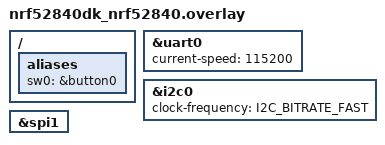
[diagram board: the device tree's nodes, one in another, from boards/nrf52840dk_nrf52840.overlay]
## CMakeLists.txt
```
cmake_minimum_required(VERSION 3.20.0)
find_package(Zephyr REQUIRED HINTS $ENV{ZEPHYR_BASE})
project(zephyr_edge_telemetry_nrf52840)

target_sources(app PRIVATE
  src/main.c
  src/app/app_config.c
  src/drivers/sensor_bus.c
  src/drivers/irq_button.c
  src/pipeline/sampler.c
  src/pipeline/pipeline_math.c
  src/pipeline/processor.c
  src/connectivity/net_client.c
  src/connectivity/ws_client.c
  src/connectivity/rest_gateway.c
  src/control/control_plane.c
)

target_include_directories(app PRIVATE include)
```

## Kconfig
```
menu "Edge Telemetry Node"

config EDGE_NODE_ID
	string "Node identifier"
	default "nrf52840-node-01"

config EDGE_SAMPLE_PERIOD_MS
	int "Sensor sampling period (ms)"
	range 10 60000
	default 100

config EDGE_REST_POLL_MS
	int "REST command poll period (ms)"
	range 1000 120000
	default 5000

config EDGE_PIPELINE_QUEUE_DEPTH
	int "Pipeline queue depth"
	range 4 128
	default 32

config EDGE_TELEMETRY_HOST
	string "Telemetry gateway host"
	default "192.168.1.10"

config EDGE_TELEMETRY_PORT
	int "Telemetry TCP/WebSocket port"
	range 1 65535
	default 9000

config EDGE_REST_PORT
	int "REST gateway port"
	range 1 65535
	default 8080

config EDGE_WS_URL
	string "WebSocket URL"
	default "/ws/telemetry"

config EDGE_REST_URL
	string "REST command URL"
	default "/api/v1/command"

endmenu
```

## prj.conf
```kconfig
CONFIG_MAIN_STACK_SIZE=4096
CONFIG_HEAP_MEM_POOL_SIZE=16384

# Logging/UART
CONFIG_SERIAL=y
CONFIG_CONSOLE=y
CONFIG_UART_CONSOLE=y
CONFIG_LOG=y
CONFIG_LOG_MODE_DEFERRED=y
CONFIG_LOG_DEFAULT_LEVEL=3
CONFIG_LOG_BUFFER_SIZE=8192

# Kernel primitives and diagnostics
CONFIG_THREAD_NAME=y
CONFIG_THREAD_MONITOR=y
CONFIG_ASSERT=y
CONFIG_INIT_STACKS=y
CONFIG_STACK_SENTINEL=y

# Watchdog strategy
CONFIG_TASK_WDT=y
CONFIG_TASK_WDT_CHANNELS=8

# Workqueue and timing
CONFIG_SYSTEM_WORKQUEUE_STACK_SIZE=3072

# Drivers/protocol buses
CONFIG_GPIO=y
CONFIG_I2C=y
CONFIG_SPI=y

# Networking and sockets
CONFIG_NETWORKING=y
CONFIG_NET_NATIVE=y
CONFIG_NET_IPV4=y
CONFIG_NET_IPV6=n
CONFIG_NET_TCP=y
CONFIG_NET_UDP=n
CONFIG_NET_SOCKETS=y
CONFIG_NET_SOCKETS_POSIX_NAMES=y
CONFIG_NET_DHCPV4=y
CONFIG_DNS_RESOLVER=y
CONFIG_NET_CONFIG_SETTINGS=y
CONFIG_NET_CONFIG_NEED_IPV4=y
CONFIG_NET_CONFIG_AUTO_INIT=y

# HTTP + WebSocket client
CONFIG_HTTP_CLIENT=y
CONFIG_WEBSOCKET_CLIENT=y
CONFIG_NET_BUF_RX_COUNT=64
CONFIG_NET_BUF_TX_COUNT=64
CONFIG_NET_PKT_RX_COUNT=16
CONFIG_NET_PKT_TX_COUNT=16

# libc helpers
CONFIG_NEWLIB_LIBC=y
CONFIG_NEWLIB_LIBC_FLOAT_PRINTF=y

# C++ support (for optional extensions)
CONFIG_CPP=y
CONFIG_STD_CPP17=y

# App defaults from Kconfig
CONFIG_EDGE_NODE_ID="nrf52840-node-01"
CONFIG_EDGE_SAMPLE_PERIOD_MS=100
CONFIG_EDGE_REST_POLL_MS=5000
CONFIG_EDGE_PIPELINE_QUEUE_DEPTH=32
CONFIG_EDGE_TELEMETRY_HOST="192.168.1.10"
CONFIG_EDGE_TELEMETRY_PORT=9000
CONFIG_EDGE_REST_PORT=8080
CONFIG_EDGE_WS_URL="/ws/telemetry"
CONFIG_EDGE_REST_URL="/api/v1/command"
```

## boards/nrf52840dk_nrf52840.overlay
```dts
/ {
	aliases {
		sw0 = &button0;
	};
};

&uart0 {
	status = "okay";
	current-speed = <115200>;
};

&i2c0 {
	status = "okay";
	clock-frequency = <I2C_BITRATE_FAST>;
};

&spi1 {
	status = "okay";
};
```

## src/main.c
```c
#include <zephyr/kernel.h>
#include <zephyr/logging/log.h>

#include <limits.h>

#include "app_config.h"
#include "control_plane.h"
#include "irq_button.h"
#include "processor.h"
#include "rest_gateway.h"
#include "rtos_channels.h"
#include "sampler.h"
#include "sensor_bus.h"
#include "ws_client.h"

LOG_MODULE_REGISTER(edge_main, LOG_LEVEL_INF);

K_MSGQ_DEFINE(edge_raw_sample_msgq,
              sizeof(struct edge_raw_sample),
              CONFIG_EDGE_PIPELINE_QUEUE_DEPTH,
              4);

K_MSGQ_DEFINE(edge_processed_sample_msgq,
              sizeof(struct edge_processed_sample),
              CONFIG_EDGE_PIPELINE_QUEUE_DEPTH,
              4);

K_MSGQ_DEFINE(edge_control_cmd_msgq,
              sizeof(struct edge_control_cmd),
              16,
              4);

K_MSGQ_DEFINE(edge_irq_event_msgq,
              sizeof(struct edge_irq_event),
              16,
              4);

K_SEM_DEFINE(edge_sample_trigger_sem, 0, UINT_MAX);
K_SEM_DEFINE(edge_work_done_sem, 0, UINT_MAX);
K_MUTEX_DEFINE(edge_network_mutex);

int main(void)
{
    int rc;

    LOG_INF("Zephyr Real-Time Edge Telemetry Node booting");

    app_config_init();

    rc = sensor_bus_init();
    if (rc < 0) {
        LOG_ERR("sensor_bus_init failed (%d)", rc);
    }

    rc = irq_button_init();
    if (rc < 0) {
        LOG_WRN("irq_button_init failed (%d), continuing", rc);
    }

    rc = control_plane_start();
    if (rc < 0) {
        LOG_ERR("control_plane_start failed (%d)", rc);
        return rc;
    }

    rc = processor_start();
    if (rc < 0) {
        LOG_ERR("processor_start failed (%d)", rc);
        return rc;
    }

    rc = sampler_start();
    if (rc < 0) {
        LOG_ERR("sampler_start failed (%d)", rc);
        return rc;
    }

    rc = ws_telemetry_start();
    if (rc < 0) {
        LOG_ERR("ws_telemetry_start failed (%d)", rc);
        return rc;
    }

    rc = rest_gateway_start();
    if (rc < 0) {
        LOG_ERR("rest_gateway_start failed (%d)", rc);
        return rc;
    }

    while (true) {
        struct edge_runtime_config cfg;
        app_config_get(&cfg);

        LOG_INF("alive: sample_period=%ums rest_poll=%ums ws=%s host=%s:%u rest_port=%u",
                cfg.sample_period_ms,
                cfg.rest_poll_ms,
                cfg.websocket_enabled ? "on" : "off",
                cfg.telemetry_host,
                cfg.telemetry_port,
                cfg.rest_port);

        k_sleep(K_SECONDS(10));
    }

    return 0;
}
```

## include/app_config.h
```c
#ifndef EDGE_APP_CONFIG_H_
#define EDGE_APP_CONFIG_H_

#include <stdbool.h>
#include <stdint.h>

struct edge_runtime_config {
    char node_id[48];
    char telemetry_host[64];
    uint16_t telemetry_port;
    uint16_t rest_port;
    char ws_url[96];
    char rest_url[96];
    uint32_t sample_period_ms;
    uint32_t rest_poll_ms;
    bool websocket_enabled;
};

void app_config_init(void);
void app_config_get(struct edge_runtime_config *out);
uint32_t app_config_get_sample_period_ms(void);
void app_config_set_sample_period_ms(uint32_t period_ms);
void app_config_set_websocket_enabled(bool enabled);

#endif
```

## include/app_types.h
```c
#ifndef EDGE_APP_TYPES_H_
#define EDGE_APP_TYPES_H_

#include <stdint.h>
#include <zephyr/sys/util.h>

#define EDGE_FLAGS_ISR_EVENT BIT(0)
#define EDGE_FLAGS_I2C_OK    BIT(1)
#define EDGE_FLAGS_SPI_OK    BIT(2)

enum edge_control_cmd_type {
    EDGE_CMD_SET_SAMPLE_PERIOD_MS = 1,
    EDGE_CMD_FORCE_FLUSH = 2,
    EDGE_CMD_FORCE_RECONNECT = 3,
};

enum edge_irq_event_type {
    EDGE_IRQ_BUTTON_PRESS = 1,
};

struct edge_raw_sample {
    uint32_t sequence;
    int64_t ts_ms;
    int16_t i2c_raw;
    int16_t spi_raw;
    uint8_t flags;
};

struct edge_processed_sample {
    uint32_t sequence;
    int64_t ts_ms;
    int16_t i2c_raw;
    int16_t spi_raw;
    int32_t fused_value;
    uint8_t quality;
    uint8_t flags;
};

struct edge_control_cmd {
    enum edge_control_cmd_type type;
    uint32_t value_u32;
};

struct edge_irq_event {
    enum edge_irq_event_type type;
    uint32_t count;
    int64_t ts_ms;
};

#endif
```

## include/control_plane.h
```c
#ifndef EDGE_CONTROL_PLANE_H_
#define EDGE_CONTROL_PLANE_H_

#include <stdbool.h>
#include <stdint.h>

int control_plane_start(void);
bool control_plane_consume_irq_latch(void);
int control_plane_watchdog_register(const char *owner, uint32_t reload_ms);
void control_plane_watchdog_feed(int channel_id);

#endif
```

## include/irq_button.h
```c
#ifndef EDGE_IRQ_BUTTON_H_
#define EDGE_IRQ_BUTTON_H_

int irq_button_init(void);

#endif
```

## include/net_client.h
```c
#ifndef EDGE_NET_CLIENT_H_
#define EDGE_NET_CLIENT_H_

#include <stdint.h>

int net_client_tcp_connect(const char *host, uint16_t port, int *sock_out);
int net_client_send_all(int sock, const uint8_t *buf, int len);
int net_client_recv_once(int sock, uint8_t *buf, int len, int timeout_ms);
void net_client_close(int *sock);

#endif
```

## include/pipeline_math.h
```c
#ifndef EDGE_PIPELINE_MATH_H_
#define EDGE_PIPELINE_MATH_H_

#include <stdint.h>

int32_t pipeline_compute_fused(int32_t previous, int16_t i2c_raw, int16_t spi_raw);

#endif
```

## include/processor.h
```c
#ifndef EDGE_PROCESSOR_H_
#define EDGE_PROCESSOR_H_

int processor_start(void);

#endif
```

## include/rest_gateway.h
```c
#ifndef EDGE_REST_GATEWAY_H_
#define EDGE_REST_GATEWAY_H_

#include "app_types.h"

int rest_gateway_start(void);
int rest_gateway_poll_command(struct edge_control_cmd *cmd_out);

#endif
```

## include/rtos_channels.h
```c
#ifndef EDGE_RTOS_CHANNELS_H_
#define EDGE_RTOS_CHANNELS_H_

#include <zephyr/kernel.h>

#include "app_types.h"

extern struct k_msgq edge_raw_sample_msgq;
extern struct k_msgq edge_processed_sample_msgq;
extern struct k_msgq edge_control_cmd_msgq;
extern struct k_msgq edge_irq_event_msgq;

extern struct k_sem edge_sample_trigger_sem;
extern struct k_sem edge_work_done_sem;

extern struct k_mutex edge_network_mutex;

#endif
```

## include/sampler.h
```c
#ifndef EDGE_SAMPLER_H_
#define EDGE_SAMPLER_H_

#include <stdint.h>

int sampler_start(void);
void sampler_update_period_ms(uint32_t period_ms);

#endif
```

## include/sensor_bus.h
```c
#ifndef EDGE_SENSOR_BUS_H_
#define EDGE_SENSOR_BUS_H_

#include "app_types.h"

int sensor_bus_init(void);
int sensor_bus_read(struct edge_raw_sample *sample);

#endif
```

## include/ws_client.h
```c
#ifndef EDGE_WS_CLIENT_H_
#define EDGE_WS_CLIENT_H_

#include <stdbool.h>
#include <stdint.h>

struct edge_ws_handle {
    int tcp_sock;
    int ws_sock;
    uint8_t tmp_buf[512];
    bool connected;
};

int ws_telemetry_start(void);
int ws_client_connect(struct edge_ws_handle *handle, const char *host, uint16_t port, const char *url);
int ws_client_send_text(struct edge_ws_handle *handle, const uint8_t *payload, uint32_t payload_len);
void ws_client_disconnect(struct edge_ws_handle *handle);

#endif
```
